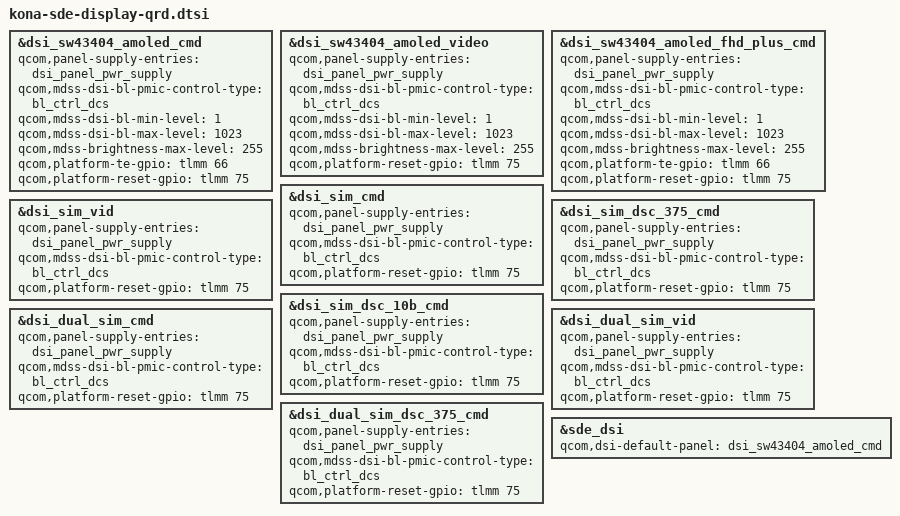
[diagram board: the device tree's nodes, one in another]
#include "kona-sde-display.dtsi"

&dsi_sw43404_amoled_cmd {
	qcom,panel-supply-entries = <&dsi_panel_pwr_supply>;
	qcom,mdss-dsi-bl-pmic-control-type = "bl_ctrl_dcs";
	qcom,mdss-dsi-bl-min-level = <1>;
	qcom,mdss-dsi-bl-max-level = <1023>;
	qcom,mdss-brightness-max-level = <255>;
	qcom,platform-te-gpio = <&tlmm 66 0>;
	qcom,platform-reset-gpio = <&tlmm 75 0>;
};

&dsi_sw43404_amoled_video {
	qcom,panel-supply-entries = <&dsi_panel_pwr_supply>;
	qcom,mdss-dsi-bl-pmic-control-type = "bl_ctrl_dcs";
	qcom,mdss-dsi-bl-min-level = <1>;
	qcom,mdss-dsi-bl-max-level = <1023>;
	qcom,mdss-brightness-max-level = <255>;
	qcom,platform-reset-gpio = <&tlmm 75 0>;
};

&dsi_sw43404_amoled_fhd_plus_cmd {
	qcom,panel-supply-entries = <&dsi_panel_pwr_supply>;
	qcom,mdss-dsi-bl-pmic-control-type = "bl_ctrl_dcs";
	qcom,mdss-dsi-bl-min-level = <1>;
	qcom,mdss-dsi-bl-max-level = <1023>;
	qcom,mdss-brightness-max-level = <255>;
	qcom,platform-te-gpio = <&tlmm 66 0>;
	qcom,platform-reset-gpio = <&tlmm 75 0>;
};

&dsi_sim_cmd {
	qcom,panel-supply-entries = <&dsi_panel_pwr_supply>;
	qcom,mdss-dsi-bl-pmic-control-type = "bl_ctrl_dcs";
	qcom,platform-reset-gpio = <&tlmm 75 0>;
};

&dsi_sim_vid {
	qcom,panel-supply-entries = <&dsi_panel_pwr_supply>;
	qcom,mdss-dsi-bl-pmic-control-type = "bl_ctrl_dcs";
	qcom,platform-reset-gpio = <&tlmm 75 0>;
};

&dsi_sim_dsc_375_cmd {
	qcom,panel-supply-entries = <&dsi_panel_pwr_supply>;
	qcom,mdss-dsi-bl-pmic-control-type = "bl_ctrl_dcs";
	qcom,platform-reset-gpio = <&tlmm 75 0>;
};

&dsi_sim_dsc_10b_cmd {
	qcom,panel-supply-entries = <&dsi_panel_pwr_supply>;
	qcom,mdss-dsi-bl-pmic-control-type = "bl_ctrl_dcs";
	qcom,platform-reset-gpio = <&tlmm 75 0>;
};

&dsi_dual_sim_cmd {
	qcom,panel-supply-entries = <&dsi_panel_pwr_supply>;
	qcom,mdss-dsi-bl-pmic-control-type = "bl_ctrl_dcs";
	qcom,platform-reset-gpio = <&tlmm 75 0>;
};

&dsi_dual_sim_vid {
	qcom,panel-supply-entries = <&dsi_panel_pwr_supply>;
	qcom,mdss-dsi-bl-pmic-control-type = "bl_ctrl_dcs";
	qcom,platform-reset-gpio = <&tlmm 75 0>;
};

&dsi_dual_sim_dsc_375_cmd {
	qcom,panel-supply-entries = <&dsi_panel_pwr_supply>;
	qcom,mdss-dsi-bl-pmic-control-type = "bl_ctrl_dcs";
	qcom,platform-reset-gpio = <&tlmm 75 0>;
};

&sde_dsi {
	qcom,dsi-default-panel = <&dsi_sw43404_amoled_cmd>;
};
